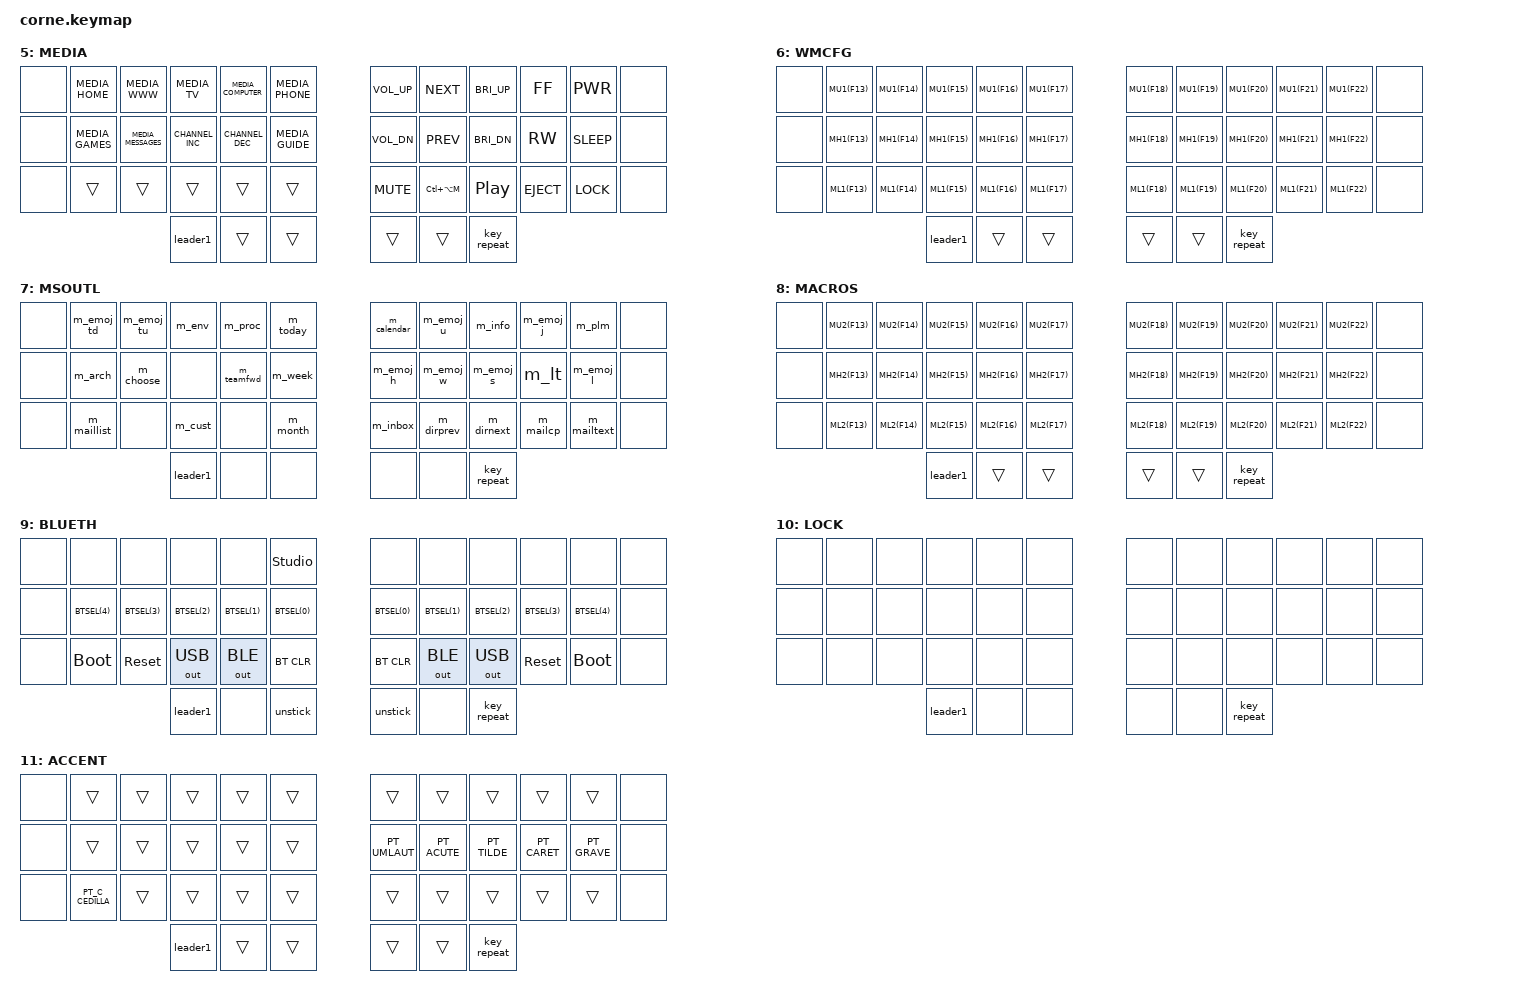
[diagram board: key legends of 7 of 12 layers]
/*
*
* Copyright (c) 2021 Darryl deHaan
* SPDX-License-Identifier: MIT
*
*/
#include <behaviors.dtsi>
#include <dt-bindings/zmk/keys.h>
#include <dt-bindings/zmk/bt.h>
#include <dt-bindings/zmk/outputs.h>
#include <dt-bindings/zmk/mouse.h>

#undef ZMK_POINTING_DEFAULT_MOVE_VAL
#define ZMK_POINTING_DEFAULT_MOVE_VAL 1500  // default: 600
#undef ZMK_POINTING_DEFAULT_SCRL_VAL
#define ZMK_POINTING_DEFAULT_SCRL_VAL 30    // default: 10
#include <dt-bindings/zmk/pointing.h>

#ifndef KEYMAP_DRAWER
#include <locale/keys_pt.h>
#endif

// https://github.com/urob/zmk-config/tree/main#timeless-homerow-mods
#define KEYS_L LT0 LT1 LT2 LT3 LT4 LM0 LM1 LM2 LM3 LM4 LB0 LB1 LB2 LB3 LB4  // left hand
#define KEYS_R RT0 RT1 RT2 RT3 RT4 RM0 RM1 RM2 RM3 RM4 RB0 RB1 RB2 RB3 RB4  // right hand
#define THUMBS LH2 LH1 LH0 RH0 RH1 RH2                                      // thumbs

#define QWERTY 0
#define NUMNAV 1
#define SYMBOL 2
#define FUNADJ 3
#define MOUSE  4
#define MEDIA  5
#define WMCFG  6
#define MSOUTL 7
#define MACROS 8
#define BLUETH 9
#define LOCK   10
#define ACCENT 11

#define COMBO_TIMEOUT 50
#define SPLIT_COMBO_TIMEOUT 75
// 3-finger chords land noticeably further apart than 2-finger ones; the extra
// slack stops S+D+F / X+C+V from missing the combo window. The idle guard -
// not the timeout - is what protects against false positives while typing.
#define LONG_COMBO_TIMEOUT 175
#define MACRO_TAP 10
#define MACRO_WAIT 0

// Upper row mods macro
#define URML(k1,k2,k3,k4,k5) &urm BLUETH k1  &urm MACROS k2  &urm MSOUTL k3  &urm WMCFG  k4  &urm MEDIA k5
#define URMR(k1,k2,k3,k4,k5) &urm MEDIA k1  &urm WMCFG  k2  &urm MSOUTL k3  &urm MACROS k4  &urm BLUETH k5
// Home row mods macro
#define HRML(k1,k2,k3,k4) &hm LGUI   k1  &hm LCTRL k2  &hm LALT  k3  &hms LSHIFT k4
#define HRMR(k1,k2,k3,k4) &hms RSHIFT k1  &hm LALT  k2  &hm LCTRL k3  &hm RGUI   k4
// Lower row mods macro
#define LRML(k1,k2,k3,k4) &kp k1  &hm RCTRL k2  &hm RALT  k3  &kp k4
#define LRMR(k1,k2,k3,k4) &kp k1  &hm RALT  k2  &hm RCTRL k3  &hm K_CMENU k4

// define AHK macro keys

// upper row for WMCFG layer (i.e. macro layer #1)
#define MU1(k) &kp LS(k)
// home row for WMCFG layer (i.e. macro layer #1)
#define MH1(k) &kp LA(k)
// lower row for WMCFG layer (i.e. macro layer #1)
#define ML1(k) &kp LC(k)

// upper row for WMCFG layer (i.e. macro layer #2)
#define MU2(k) &kp LG(LS(k))
// home row for WMCFG layer (i.e. macro layer #2)
#define MH2(k) &kp LG(LA(k))
// lower row for WMCFG layer (i.e. macro layer #2)
#define ML2(k) &kp LG(LC(k))

// more macros to shorten the definitions
#define BTSEL(profile) &bt BT_SEL profile
#define BTCLR &bt BT_CLR
#define OUTUSB &out OUT_USB
#define OUTBLE &out OUT_BLE

// TODO: add generic mechanism to lock layers
// TODO: add 2x rotary encoder - use Fxx or LANG1/LANG2 as free keycodes for AHK
// TODO: add leader key: move AHK into keyboard to use all all machines - use C_AL_CALC/C_AC_SEARCH/C_AL_CAL
// TODO: add trackball

// Sticky layer tuning: accent layer should not linger forever if you get
// distracted mid-composition. quick-release (the ZMK default for sticky
// layers) drops the layer as soon as the next key is pressed.
&sl {
    release-after-ms = <1500>;
};

/ {
// -------------------CORNE---------------------------------------
// |    |  1 |  2 |  3 |  4 |  5 | |  6 |  7 |  8 |  9 | 10 |    |
// |    | 13 | 14 | 15 | 16 | 17 | | 18 | 19 | 20 | 21 | 22 |    |
// |    | 25 | 26 | 27 | 28 | 29 | | 30 | 31 | 32 | 33 | 34 |    |
// |    |    |    | 36 | 37 | 38 | | 39 | 40 | 41 |    |    |    |

// -------------------TEMPEST-------------------------------------
//      |  0 |  1 |  2 |  3 |  4 | |  5 |  6 |  7 |  8 |  9 |
//      | 10 | 11 | 12 | 13 | 14 | | 15 | 16 | 17 | 18 | 19 |
//      | 20 | 21 | 22 | 23 | 24 | | 25 | 26 | 27 | 28 | 29 |
//                | 30 | 31 | 32 | | 33 | 34 | 35 |

// -------------------SWEEP---------------------------------------
//      |  0 |  1 |  2 |  3 |  4 | |  5 |  6 |  7 |  8 |  9 |
//      | 10 | 11 | 12 | 13 | 14 | | 15 | 16 | 17 | 18 | 19 |
//      | 20 | 21 | 22 | 23 | 24 | | 25 | 26 | 27 | 28 | 29 |
//                     | 30 | 31 | | 32 | 33 |
    combos {
        compatible = "zmk,combos";
        combo_toggle_lock_left {
                  timeout-ms = <COMBO_TIMEOUT>;
                  key-positions = <1 5 38>;  // ONLY-FOR-CORNE
                  require-prior-idle-ms = <150>;
                  layers = <QWERTY LOCK>;
                  bindings = <&tog LOCK>;
        };
        combo_toggle_lock_right {
                  timeout-ms = <COMBO_TIMEOUT>;
                  key-positions = <6 10 39>;  // ONLY-FOR-CORNE
                  require-prior-idle-ms = <150>;
                  layers = <QWERTY LOCK>;
                  bindings = <&tog LOCK>;
        };
        combo_esc {
                  timeout-ms = <COMBO_TIMEOUT>;
                  key-positions = <1 2>;  // ONLY-FOR-CORNE
                  require-prior-idle-ms = <120>;
                  layers = <QWERTY>;
                  bindings = <&kp ESC>;
        };
        combo_tab {
                  timeout-ms = <COMBO_TIMEOUT>;
                  key-positions = <13 14>;  // ONLY-FOR-CORNE
                  require-prior-idle-ms = <120>;
                  layers = <QWERTY>;
                  bindings = <&kp TAB>;
        };
        combo_ret {
                  timeout-ms = <COMBO_TIMEOUT>;
                  key-positions = <6 7>;  // ONLY-FOR-CORNE
                  require-prior-idle-ms = <120>;
                  layers = <QWERTY>;
                  bindings = <&kp RET>;
        };
        combo_capsword {
                  timeout-ms = <SPLIT_COMBO_TIMEOUT>;
                  key-positions = <17 18>;  // ONLY-FOR-CORNE
                  require-prior-idle-ms = <200>;
                  layers = <QWERTY>;
                  bindings = <&capsw>;
        };
        combo_bspc {
                  timeout-ms = <COMBO_TIMEOUT>;
                  key-positions = <21 22>;  // ONLY-FOR-CORNE
                  require-prior-idle-ms = <150>;
                  layers = <QWERTY>;
                  bindings = <&kp BSPC>;
        };
        combo_ctrlbspc {
                  timeout-ms = <COMBO_TIMEOUT>;
                  key-positions = <19 20>;  // ONLY-FOR-CORNE
                  require-prior-idle-ms = <150>;
                  layers = <QWERTY>;
                  bindings = <&kp LC(BSPC)>;
        };
        combo_del {
                  timeout-ms = <COMBO_TIMEOUT>;
                  key-positions = <9 10>;  // ONLY-FOR-CORNE
                  require-prior-idle-ms = <150>;
                  layers = <QWERTY>;
                  bindings = <&kp DEL>;
        };
        combo_repeat_right {
                  timeout-ms = <COMBO_TIMEOUT>;
                  key-positions = <18 19>;  // ONLY-FOR-CORNE
                  require-prior-idle-ms = <150>;
                  layers = <QWERTY>;
                  bindings = <&key_repeat>;
        };
        combo_sz {
                  timeout-ms = <COMBO_TIMEOUT>;
                  key-positions = <27 28>;  // ONLY-FOR-CORNE
                  require-prior-idle-ms = <100>;
                  layers = <QWERTY>;
                  bindings = <&kp RA(S)>;
        };
        combo_pup {
                  timeout-ms = <COMBO_TIMEOUT>;
                  key-positions = <4 5>;  // ONLY-FOR-CORNE
                  require-prior-idle-ms = <150>;
                  layers = <QWERTY>;
                  bindings = <&kp PG_UP>;
        };
        combo_down {
                  timeout-ms = <COMBO_TIMEOUT>;
                  key-positions = <16 17>;  // ONLY-FOR-CORNE
                  require-prior-idle-ms = <150>;
                  layers = <QWERTY>;
                  bindings = <&kp PG_DN>;
        };
        combo_prtwin {
                  timeout-ms = <COMBO_TIMEOUT>;
                  key-positions = <25 26>;  // ONLY-FOR-CORNE
                  require-prior-idle-ms = <150>;
                  layers = <QWERTY>;
                  bindings = <&kp PSCRN>;
        };
        combo_ctrlshiftc {
                  timeout-ms = <LONG_COMBO_TIMEOUT>;
                  key-positions = <14 15 16>;  // ONLY-FOR-CORNE
                  require-prior-idle-ms = <200>;
                  layers = <QWERTY>;
                  bindings = <&kp LC(LS(C))>;
        };
        // Ctrl-Shift-X (cut). W+E+R on tempest. Previously this was a double-tap
        // of the copy combo via &td_ctrl_cx; tap-dances cannot be driven by
        // combos (the combo's press/release is not a clean single tap, which
        // leaked a bare "c" and left Ctrl/Shift latched).
        combo_ctrlshiftx {
                  timeout-ms = <LONG_COMBO_TIMEOUT>;
                  key-positions = <4 5 6>;   // ONLY-FOR-CORNE
                  require-prior-idle-ms = <200>;
                  layers = <QWERTY>;
                  bindings = <&kp LC(LS(X))>;
        };
        combo_ctrlshiftv {
                  timeout-ms = <LONG_COMBO_TIMEOUT>;
                  key-positions = <26 27 28>;  // ONLY-FOR-CORNE
                  require-prior-idle-ms = <200>;
                  layers = <QWERTY>;
                  bindings = <&kp LC(LS(V))>;
        };
        combo_ctrl_a {
                  timeout-ms = <COMBO_TIMEOUT>;
                  key-positions = <31 32>;  // ONLY-FOR-CORNE
                  require-prior-idle-ms = <150>;
                  layers = <QWERTY>;
                  bindings = <&kp LC(A)>;
        };
        combo_ctrl_z {
                  timeout-ms = <COMBO_TIMEOUT>;
                  key-positions = <32 33>;  // ONLY-FOR-CORNE
                  require-prior-idle-ms = <150>;
                  layers = <QWERTY>;
                  bindings = <&kp LC(Z)>;
        };
        // Leader key 2 via the N+M combo (tempest positions 25/26).
        // NOTE: this partially overlaps combo_ctrl_a <26 27>. ZMK supports
        // overlapping combos, but N+M vs M+ may resolve ambiguously.
        combo_leader2 {
                  timeout-ms = <COMBO_TIMEOUT>;
                  key-positions = <20 21>;  // ONLY-FOR-CORNE
                  require-prior-idle-ms = <150>;
                  layers = <QWERTY>;
                  bindings = <&leader2>;
        };
    };

    macros {
        ZMK_MACRO(m_today,
                wait-ms = <MACRO_WAIT>;
                tap-ms = <MACRO_TAP>;
                bindings
                    = <&macro_press &kp LCTRL>
                    , <&macro_tap &kp F2>
                    , <&macro_release &kp LCTRL>
                    , <&macro_wait_time 300>
                    , <&macro_press &kp LCTRL &kp LSHIFT>
                    , <&macro_tap &kp N8>
                    , <&macro_release &kp LCTRL &kp LSHIFT>
                    ;
                )
        ZMK_MACRO(m_week,
                wait-ms = <MACRO_WAIT>;
                tap-ms = <MACRO_TAP>;
                bindings
                    = <&macro_press &kp LCTRL>
                    , <&macro_tap &kp F3>
                    , <&macro_release &kp LCTRL>
                    , <&macro_wait_time 300>
                    , <&macro_press &kp LCTRL &kp LSHIFT>
                    , <&macro_tap &kp N8>
                    , <&macro_release &kp LCTRL &kp LSHIFT>
                    ;
                )
        ZMK_MACRO(m_month,
                wait-ms = <MACRO_WAIT>;
                tap-ms = <MACRO_TAP>;
                bindings
                    = <&macro_press &kp LCTRL>
                    , <&macro_tap &kp F4>
                    , <&macro_release &kp LCTRL>
                    , <&macro_wait_time 300>
                    , <&macro_press &kp LCTRL &kp LSHIFT>
                    , <&macro_tap &kp N8>
                    , <&macro_release &kp LCTRL &kp LSHIFT>
                    ;
                )
        ZMK_MACRO(m_proc,
                wait-ms = <MACRO_WAIT>;
                tap-ms = <MACRO_TAP>;
                bindings
                    = <&macro_press &kp LCTRL &kp LSHIFT>
                    , <&macro_tap &kp N7>
                    , <&macro_release &kp LCTRL &kp LSHIFT>
                    ;
                )
        ZMK_MACRO(m_arch,
                wait-ms = <MACRO_WAIT>;
                tap-ms = <MACRO_TAP>;
                bindings
                    = <&macro_press &kp LCTRL &kp LSHIFT>
                    , <&macro_tap &kp N6>
                    , <&macro_release &kp LCTRL &kp LSHIFT>
                    ;
                )
        ZMK_MACRO(m_plm,
                wait-ms = <MACRO_WAIT>;
                tap-ms = <MACRO_TAP>;
                bindings
                    = <&macro_press &kp LCTRL &kp LSHIFT>
                    , <&macro_tap &kp N4>
                    , <&macro_release &kp LCTRL &kp LSHIFT>
                    ;
                )
        ZMK_MACRO(m_lt,
                wait-ms = <MACRO_WAIT>;
                tap-ms = <MACRO_TAP>;
                bindings
                    = <&macro_press &kp LCTRL &kp LSHIFT>
                    , <&macro_tap &kp N5>
                    , <&macro_release &kp LCTRL &kp LSHIFT>
                    ;
                )
        ZMK_MACRO(m_cust,
                wait-ms = <MACRO_WAIT>;
                tap-ms = <MACRO_TAP>;
                bindings
                    = <&macro_press &kp LCTRL &kp LSHIFT>
                    , <&macro_tap &kp N2>
                    , <&macro_release &kp LCTRL &kp LSHIFT>
                    ;
                )
        ZMK_MACRO(m_info,
                wait-ms = <MACRO_WAIT>;
                tap-ms = <MACRO_TAP>;
                bindings
                    = <&macro_press &kp LCTRL &kp LSHIFT>
                    , <&macro_tap &kp N3>
                    , <&macro_release &kp LCTRL &kp LSHIFT>
                    ;
                )
        ZMK_MACRO(m_env,
                wait-ms = <MACRO_WAIT>;
                tap-ms = <MACRO_TAP>;
                bindings
                    = <&macro_press &kp LCTRL &kp LSHIFT>
                    , <&macro_tap &kp N1>
                    , <&macro_release &kp LCTRL &kp LSHIFT>
                    ;
                )
        ZMK_MACRO(m_choose,
                wait-ms = <MACRO_WAIT>;
                tap-ms = <MACRO_TAP>;
                bindings
                    = <&macro_press &kp LCTRL &kp LSHIFT>
                    , <&macro_tap &kp N9>
                    , <&macro_release &kp LCTRL &kp LSHIFT>
                    ;
                )
        ZMK_MACRO(m_maillist,
                wait-ms = <MACRO_WAIT>;
                tap-ms = <MACRO_TAP>;
                bindings = <&kp LS(F6)>;
                )
        ZMK_MACRO(m_mailtext,
                wait-ms = <MACRO_WAIT>;
                tap-ms = <MACRO_TAP>;
                bindings = <&kp F6>;
                )
        ZMK_MACRO(m_teamfwd,
                wait-ms = <MACRO_WAIT>;
                tap-ms = <MACRO_TAP>;
                bindings = <&kp LS(F24)>;
                )
        ZMK_MACRO(m_calendar,
                wait-ms = <MACRO_WAIT>;
                tap-ms = <MACRO_TAP>;
                bindings = <&kp LC(N2)>;
                )
        ZMK_MACRO(m_inbox,
                wait-ms = <MACRO_WAIT>;
                tap-ms = <MACRO_TAP>;
                bindings = <&kp LC(LS(I))>;
                )
        ZMK_MACRO(m_dirprev,
                wait-ms = <MACRO_WAIT>;
                tap-ms = <MACRO_TAP>;
                bindings = <&kp LA(LEFT)>;
                )
        ZMK_MACRO(m_dirnext,
                wait-ms = <MACRO_WAIT>;
                tap-ms = <MACRO_TAP>;
                bindings = <&kp LC(RIGHT)>;
                )
        ZMK_MACRO(m_mailcp,
                wait-ms = <MACRO_WAIT>;
                tap-ms = <MACRO_TAP>;
                bindings = <&kp LC(LS(Y))>;
                )
        ZMK_MACRO(m_emoj_td,
                wait-ms = <MACRO_WAIT>;
                tap-ms = <MACRO_TAP>;
                bindings = <&kp RA(N9) &kp E &kp T &kp D &kp SPACE &kp BSPC>;
                )
        ZMK_MACRO(m_emoj_tu,
                wait-ms = <MACRO_WAIT>;
                tap-ms = <MACRO_TAP>;
                bindings = <&kp RA(N9) &kp E &kp T &kp U &kp SPACE &kp BSPC>;
                )
        ZMK_MACRO(m_emoj_u,
                wait-ms = <MACRO_WAIT>;
                tap-ms = <MACRO_TAP>;
                bindings = <&kp RA(N9) &kp E &kp T &kp SPACE &kp BSPC>;
                )
        ZMK_MACRO(m_emoj_j,
                wait-ms = <MACRO_WAIT>;
                tap-ms = <MACRO_TAP>;
                bindings = <&kp RA(N9) &kp E &kp J &kp SPACE &kp BSPC>;
                )
        ZMK_MACRO(m_emoj_l,
                wait-ms = <MACRO_WAIT>;
                tap-ms = <MACRO_TAP>;
                bindings = <&kp RA(N9) &kp E &kp L &kp SPACE &kp BSPC>;
                )
        ZMK_MACRO(m_emoj_h,
                wait-ms = <MACRO_WAIT>;
                tap-ms = <MACRO_TAP>;
                bindings = <&kp RA(N9) &kp E &kp H &kp SPACE &kp BSPC>;
                )
        ZMK_MACRO(m_emoj_s,
                wait-ms = <MACRO_WAIT>;
                tap-ms = <MACRO_TAP>;
                bindings = <&kp RA(N9) &kp E &kp S &kp SPACE &kp BSPC>;
                )
        ZMK_MACRO(m_emoj_w,
                wait-ms = <MACRO_WAIT>;
                tap-ms = <MACRO_TAP>;
                bindings = <&kp RA(N9) &kp E &kp W &kp SPACE &kp BSPC>;
                )
        ZMK_MACRO(m_dblclk,
                wait-ms = <MACRO_WAIT>;
                tap-ms = <MACRO_TAP>;
                bindings = <&mkp LCLK &mkp LCLK>;
                )
        // Cumps, / Heiko
        ZMK_MACRO(m_sig_cumps,
                wait-ms = <MACRO_WAIT>;
                tap-ms = <MACRO_TAP>;
        bindings = <&kp LS(C) &kp U &kp M &kp P &kp S &kp COMMA &kp RET &kp LS(H)
                    &kp E &kp I &kp K &kp O>;
                )

        // Muito obrigado, / Heiko
        ZMK_MACRO(m_sig_mo,
                wait-ms = <MACRO_WAIT>;
                tap-ms = <MACRO_TAP>;
        bindings = <&kp LS(M) &kp U &kp I &kp T &kp O &kp SPACE &kp O &kp B
                    &kp R &kp I &kp G &kp A &kp D &kp O &kp COMMA &kp RET
                    &kp LS(H) &kp E &kp I &kp K &kp O>;
                )

        // Obrigado, / Heiko
        ZMK_MACRO(m_sig_o,
                wait-ms = <MACRO_WAIT>;
                tap-ms = <MACRO_TAP>;
        bindings = <&kp LS(O) &kp B &kp R &kp I &kp G &kp A &kp D &kp O
                    &kp COMMA &kp RET &kp LS(H) &kp E &kp I &kp K &kp O>;
                )

        // Obrigado e cumps, / Heiko
        ZMK_MACRO(m_sig_oc,
                wait-ms = <MACRO_WAIT>;
                tap-ms = <MACRO_TAP>;
        bindings = <&kp LS(O) &kp B &kp R &kp I &kp G &kp A &kp D &kp O
                    &kp SPACE &kp E &kp SPACE &kp C &kp U &kp M &kp P &kp S
                    &kp COMMA &kp RET &kp LS(H) &kp E &kp I &kp K &kp O>;
                )

        // Cumps e obrigado, / Heiko
        ZMK_MACRO(m_sig_co,
                wait-ms = <MACRO_WAIT>;
                tap-ms = <MACRO_TAP>;
        bindings = <&kp LS(C) &kp U &kp M &kp P &kp S &kp SPACE &kp E &kp SPACE
                    &kp O &kp B &kp R &kp I &kp G &kp A &kp D &kp O
                    &kp COMMA &kp RET &kp LS(H) &kp E &kp I &kp K &kp O>;
                )

        // Best regards, / Heiko
        ZMK_MACRO(m_sig_br,
                wait-ms = <MACRO_WAIT>;
                tap-ms = <MACRO_TAP>;
        bindings = <&kp LS(B) &kp E &kp S &kp T &kp SPACE &kp R &kp E &kp G
                    &kp A &kp R &kp D &kp S &kp COMMA &kp RET &kp LS(H) &kp E
                    &kp I &kp K &kp O>;
                )

        // Thank you, / Heiko
        ZMK_MACRO(m_sig_ty,
                wait-ms = <MACRO_WAIT>;
                tap-ms = <MACRO_TAP>;
        bindings = <&kp LS(T) &kp H &kp A &kp N &kp K &kp SPACE &kp Y &kp O
                    &kp U &kp COMMA &kp RET &kp LS(H) &kp E &kp I &kp K &kp O>;
                )

        // Thank you and best regards, / Heiko
        ZMK_MACRO(m_sig_tb,
                wait-ms = <MACRO_WAIT>;
                tap-ms = <MACRO_TAP>;
        bindings = <&kp LS(T) &kp H &kp A &kp N &kp K &kp SPACE &kp Y &kp O
                    &kp U &kp SPACE &kp A &kp N &kp D &kp SPACE &kp B &kp E
                    &kp S &kp T &kp SPACE &kp R &kp E &kp G &kp A &kp R
                    &kp D &kp S &kp COMMA &kp RET &kp LS(H) &kp E &kp I &kp K
                    &kp O>;
                )

        // Thank you, / Heiko Riemer
        ZMK_MACRO(m_sig_th,
                wait-ms = <MACRO_WAIT>;
                tap-ms = <MACRO_TAP>;
        bindings = <&kp LS(T) &kp H &kp A &kp N &kp K &kp SPACE &kp Y &kp O
                    &kp U &kp COMMA &kp RET &kp LS(H) &kp E &kp I &kp K &kp O
                    &kp SPACE &kp LS(R) &kp I &kp E &kp M &kp E &kp R>;
                )

        // You're Welcome
        ZMK_MACRO(m_sig_yw,
                wait-ms = <MACRO_WAIT>;
                tap-ms = <MACRO_TAP>;
        bindings = <&kp LS(Y) &kp O &kp U &kp SQT &kp R &kp E &kp SPACE &kp LS(W)
                    &kp E &kp L &kp C &kp O &kp M &kp E>;
                )

        // Ctrl-B "Agenda:" Ctrl-B, then bullet
        ZMK_MACRO(m_ag,
                wait-ms = <MACRO_WAIT>;
                tap-ms = <MACRO_TAP>;
                bindings = <&kp LC(B) &kp A &kp G &kp E &kp N &kp D &kp A &kp PT_COLON &kp LC(B) &kp RET &kp LC(LS(L))>;
                )

        // Ctrl-B "Objective:" Ctrl-B, then bullet
        ZMK_MACRO(m_ob,
                wait-ms = <MACRO_WAIT>;
                tap-ms = <MACRO_TAP>;
                bindings = <&kp LC(B) &kp O &kp B &kp J &kp E &kp C &kp T &kp I &kp V &kp E &kp PT_COLON &kp LC(B) &kp RET &kp LC(LS(L))>;
                )

        // Ctrl-B "Actions:" Ctrl-B, then bullet
        ZMK_MACRO(m_ac,
                wait-ms = <MACRO_WAIT>;
                tap-ms = <MACRO_TAP>;
                bindings = <&kp LC(B) &kp A &kp C &kp T &kp I &kp O &kp N &kp S &kp PT_COLON &kp LC(B) &kp RET &kp LC(LS(L))>;
                )

        // Agenda: block then Objective: block
        ZMK_MACRO(m_ao,
                wait-ms = <MACRO_WAIT>;
                tap-ms = <MACRO_TAP>;
                bindings = <&kp LC(B) &kp A &kp G &kp E &kp N &kp D &kp A &kp PT_COLON &kp LC(B) &kp RET &kp LC(LS(L)) &kp SPACE &kp RET &kp RET &kp RET &kp LC(B) &kp O &kp B &kp J &kp E &kp C &kp T &kp I &kp V &kp E &kp PT_COLON &kp LC(B) &kp RET &kp LC(LS(L))>;
                )
        ZMK_MACRO(m_de_ue,
                wait-ms = <MACRO_WAIT>;
                tap-ms = <MACRO_TAP>;
                bindings = <&kp PT_UMLAUT &kp U>;
                )
    };

    behaviors {
        spc_ret: space_return {
            compatible = "zmk,behavior-mod-morph";
            #binding-cells = <0>;
            bindings = <&kp PT_SPACE>, <&kp RET>;
            mods = <(MOD_LALT)>;
        };
        bspc_del: backspace_delete {
            compatible = "zmk,behavior-mod-morph";
            #binding-cells = <0>;
            bindings = <&kp BACKSPACE>, <&kp DELETE>;
            mods = <(MOD_LSFT|MOD_RSFT)>;
            /*keep-mods = <(MOD_RSFT)>;*/
        };
        laquo_raquo: laquo_raquo {
            compatible = "zmk,behavior-mod-morph";
            #binding-cells = <0>;
            bindings = <&kp PT_LAQUO>, <&kp PT_RAQUO>;
            mods = <(MOD_LSFT|MOD_RSFT)>;
        };
        ordm_ordf: ordm_ordf {
            compatible = "zmk,behavior-mod-morph";
            #binding-cells = <0>;
            bindings = <&kp PT_ORDM>, <&kp PT_ORDF>;
            mods = <(MOD_LSFT|MOD_RSFT)>;
        };
        hm: homerow_mods {
            compatible = "zmk,behavior-hold-tap";
            #binding-cells = <2>;
            tapping-term-ms = <210>;
            require-prior-idle-ms = <150>;
            flavor = "tap-preferred";
            bindings = <&kp>, <&kp>;
        };
        hms: homerow_mod_shift {
            compatible = "zmk,behavior-hold-tap";
            #binding-cells = <2>;
            tapping-term-ms = <200>;
            require-prior-idle-ms = <125>;
            flavor = "balanced";
            bindings = <&kp>, <&kp>;
        };
        urm: upper_row_mods {
            compatible = "zmk,behavior-hold-tap";
            #binding-cells = <2>;
            tapping-term-ms = <250>;
            require-prior-idle-ms = <150>;
            flavor = "tap-preferred";
            bindings = <&mo>, <&kp>;
        };
        trm: thumb_row_mods {
            compatible = "zmk,behavior-hold-tap";
            #binding-cells = <2>;
            tapping-term-ms = <250>;
            require-prior-idle-ms = <50>;
            flavor = "tap-preferred";
            bindings = <&mo>, <&kp>;
         };
         skm: space_key_mod {  //TODO(heiko): not yet used
            compatible = "zmk,behavior-hold-tap";
            #binding-cells = <2>;
            tapping-term-ms = <250>;
            require-prior-idle-ms = <150>;
            flavor = "tap-preferred";
            /*bindings = <&mo>, <&spc_ret>;*/
            bindings = <&mo>, <&kp>;
        };
        unstick: unstick {
            compatible = "zmk,behavior-macro";
            #binding-cells = <0>;
            bindings = <&kp LSHIFT &kp RSHIFT &kp LCTRL &kp RCTRL &kp LALT &kp RALT &kp LGUI &kp RGUI>;
        };
        capsw: behavior_caps_word {
            compatible = "zmk,behavior-caps-word";
            #binding-cells = <0>;
            continue-list = <BACKSPACE DELETE PT_MINUS PT_UNDER>;
        };
        // Leader key instances. Reach the first instance with the left outer
        // thumb and the second with the N+M combo. Note: generate_keymaps.sh
        // rewrites the &leader1 placeholder token to this behavior, so the behavior
        // must stay defined here in the shared source.
        //
        // leader1 = the AHK replacement sequences (previously typed as "]xx").
        //           The leader key itself replaces the "]" prefix, so "]c"
        //           becomes leader1 then C.
        leader1: leader1 {
            compatible = "zmk,behavior-leader-key";
            #binding-cells = <0>;
            // Portuguese / English sign-offs
            cu  { sequence = <C U>;   bindings = <&m_sig_cumps>; };
            obr { sequence = <O B R>; bindings = <&m_sig_o>; };
            mo  { sequence = <M O>;   bindings = <&m_sig_mo>; };
            oc  { sequence = <O C>;   bindings = <&m_sig_oc>; };
            co  { sequence = <C O>;   bindings = <&m_sig_co>; };
            br  { sequence = <B R>;   bindings = <&m_sig_br>; };
            ty  { sequence = <T Y>;   bindings = <&m_sig_ty>; };
            tb  { sequence = <T B>;   bindings = <&m_sig_tb>; };
            th  { sequence = <T H>;   bindings = <&m_sig_th>; };
            yw  { sequence = <Y W>;   bindings = <&m_sig_yw>; };
            // MS Outlook headings (AHK "^b" = Ctrl-B)
            ag  { sequence = <A G>;   bindings = <&m_ag>; };
            obj { sequence = <O B J>; bindings = <&m_ob>; };
            ao  { sequence = <A O>;   bindings = <&m_ao>; };
            ac  { sequence = <A C>;   bindings = <&m_ac>; };
        };

        // leader2 = system / bluetooth sequences.
        leader2: leader2 {
            compatible = "zmk,behavior-leader-key";
            #binding-cells = <0>;
            usb { sequence = <U S B>; bindings = <&out OUT_USB>; };
            ble { sequence = <B L E>; bindings = <&out OUT_BLE>; };
            bt0 { sequence = <B N0>; bindings = <&bt BT_SEL 0>; };
            bt1 { sequence = <B N1>; bindings = <&bt BT_SEL 1>; };
            bt2 { sequence = <B N2>; bindings = <&bt BT_SEL 2>; };
            btc { sequence = <C L E A R>; bindings = <&bt BT_CLR>; };
            boot { sequence = <B O O T>; bindings = <&bootloader>; };
            reset { sequence = <R E S E T>; bindings = <&sys_reset>; };
        };

    };

        keymap {
                compatible = "zmk,keymap";

                default_layer {
                        display-name = "QWERTY";
// -------------------------------------------------------------------------------
// |      |Q/L9 |W/L8 |E/L7 |R/L6 |T/L5 |   |Y/L5 |U/L6 |I/L7 |O/L8 |P/L9 |      |
// |      |A/LG |S/LC |D/LA |F/LS |  G  |   |  H  |J/RS |K/LA |L/LC |;/RG |      |
// |      |Z/LS |X/RC |C/RA |  V  |  B  |   |  N  | M   |,/RA |./RC |//MENU|     |
//              |     | L1  |S/LC |              |SPC/L4| L2  |     |
                        bindings = <
&none URML(Q, W, E, R, T)        URMR(Y, U, I, O, P) &none
&none HRML(A, S, D, F) &kp G     &kp H HRMR(J, K, L, PT_C_CEDILLA) &none
&none LRML(Z, X, C, V) &kp B     &kp N LRMR(M, COMMA, DOT, PT_MINUS) &none
  &leader1 &mo NUMNAV  &kp BACKSPACE     &skm MOUSE SPACE &mo SYMBOL &key_repeat
                        >;
                };

                numnav_layer {
                        display-name = "NUMNAV";
// -------------------------------------------------------------------------------
// |      |  1  |  2  |  3  |  4  |  5  |   |  6  |  7  |  8  |  9  |  0  |      |
// |      |     |     |     |     |     |   |LF/RS|DN/LA|UP/LC|RT/LG|     |      |
// |      |     |     |     |     |     |   |  «  |  º  |     |     |     |      |
//                    |     |     |     |   |     | L3  |     |
                        bindings = <
 &none &kp N1 &kp N2 &kp N3  &kp N4 &kp N5     &kp N6  &kp N7  &kp N8  &kp N9  &kp N0  &none
 &none &trans &trans &trans &trans &trans      &kp LEFT HRMR(DOWN, UP, RIGHT, RIGHT) &none
 &none &trans &trans &trans &trans &trans      &laquo_raquo &ordm_ordf &trans &trans &trans &none
                     &leader1  &trans  &trans    &trans &mo FUNADJ &key_repeat
                        >;
                };

                symbol_layer {
                        display-name = "SYMBOL";
// -------------------------------------------------------------------------------
// |      |  !  |  "@ |  #  |  $  |  %  |   |  &^ |  /& |  (* |  )( |  =) |      |
// |      |  <  |  [  |  {  |  (  | ACC |   |  '- |  \= |  *{ |  `} |  ^| |      |
// |      |  >  |  ]  |  }  |  )  |  ~  |   |  ?_ |  |+ |  +[ |  '] |  ~\ |      |
//                    |     | L3  | DEL |   |     |     |     |
                        bindings = <
&none &kp PT_EXCL &kp PT_DQT &kp PT_HASH &kp PT_DLLR &kp PT_PRCNT  &kp PT_AMPS &kp PT_FSLH &kp PT_LPAR &kp PT_RPAR &kp PT_EQUAL &none
&none HRML(PT_LT, PT_LBKT, PT_LBRC, PT_LPAR) &sl ACCENT  &kp PT_SQT HRMR(PT_BSLH, PT_STAR, PT_AT, PT_UNDER) &none
&none LRML(PT_GT, PT_RBKT, PT_RBRC, PT_RPAR) &kp PT_TILDE  &kp PT_QMARK LRMR(PT_PIPE, PT_PLUS, PT_EURO, PT_SECT) &none
                        &leader1 &mo FUNADJ &hm RCTRL DEL   &trans  &trans   &key_repeat
                        >;
                };

                funadj_layer {
                        display-name = "FUNADJ";
// -------------------------------------------------------------------------------
// |      | F1  | F2  | F3  | F4  | F5  |   | F6  | F7  | F8  | F9  | F10 |      |
// |      | F11 | F12 | F13 | F14 | F15 |   | F16 | F17 | F18 | F19 | F20 |      |
// |      |PSCRN|SLCK |BREAK|     | CAPS|   | HOME| PDN | PUP | END | INS |      |
//                    |     |     |     |   |     |     |     |
                        bindings = <
&none &kp F1 &kp F2 &kp F3 &kp F4 &kp F5       &kp F6 &kp F7 &kp F8 &kp F9 &kp F10 &none
&none HRML(F11, F12, F13, F14) &kp F15         &kp F16 HRMR(F17, F18, F19, F20) &none
&none LRML(PSCRN, SLCK, PAUSE_BREAK, CAPS) &trans  &kp HOME LRMR(PG_DN, PG_UP, END, INS) &none
                       &leader1 &trans &trans  &trans &trans &key_repeat
                        >;
                };

                mouse_layer {
                        display-name = "MOUSE";
// -------------------------------------------------------------------------------
// |      |     |     |  `  |  ´  |  ^  |   |     |     |     |     |     |      |
// |      | SUP | LC  | LA  | LS  |  ¨  |   | LF  | DN  | UP  | RT  | SUP |      |
// |      | SDN | RCLK| MCLK| LCLK|  ~  |   |     | LCLK| MCLK| RCLK| SDN |      |
//                    |     |     |     |   |     |     |     |
 // &none &trans &trans &kp LS(RBKT)  &kp RBKT &kp LS(BSLH)     &trans  &trans  &trans  &trans  &trans  &none
 // &none &msc SCRL_UP &kp LCTRL &kp LALT &kp LSHIFT &kp RA(LBKT)  &mmv MOVE_LEFT &mmv MOVE_DOWN &mmv MOVE_UP &mmv MOVE_RIGHT &msc SCRL_UP &none
 // &none &msc SCRL_DOWN &mkp RCLK &mkp MCLK &mkp LCLK &kp BSLH   &trans  &mkp LCLK &mkp MCLK &mkp RCLK &msc SCRL_DOWN &none
                        bindings = <
 &none &trans &trans &kp PT_GRAVE  &kp PT_ACUTE &kp PT_CARET  &msc SCRL_LEFT  &msc SCRL_DOWN  &msc SCRL_UP  &msc SCRL_RIGHT  &kp LC(LA(LS(J)))  &none
 &none &mkp MB5 &kp LCTRL &kp LALT &kp LSHIFT &kp PT_UMLAUT  &mmv MOVE_LEFT &mmv MOVE_DOWN &mmv MOVE_UP &mmv MOVE_RIGHT &mkp MB5 &none
 &none &mkp MB4 &mkp RCLK &mkp MCLK &mkp LCLK &kp PT_TILDE   &m_dblclk  &mkp LCLK &mkp MCLK &mkp RCLK &mkp MB4 &none
                     &leader1  &trans  &trans     &trans &trans &key_repeat
                        >;
                };

                config_layer {
                        display-name = "MEDIA";
// -------------------------------------------------------------------------------
// |      |     |     |     |     |     |   | VUP | NXT | BUP |     |     |      |
// |      |     |     |     |     |     |   | VDN | PRE | BDN |     |     |      |
// |      | PWR | SLP | LCK |     |     |   | MT  |     | PP  |     | EJC |      |
//                    |     |     |     |   |     |     |     |
                        bindings = <
&none &kp C_MEDIA_HOME &kp C_MEDIA_WWW &kp C_MEDIA_TV &kp C_MEDIA_COMPUTER &kp C_MEDIA_PHONE  &kp C_VOL_UP &kp C_NEXT &kp C_BRI_UP &kp C_FF &kp C_PWR &none
&none &kp C_MEDIA_GAMES &kp C_MEDIA_MESSAGES &kp C_CHANNEL_INC &kp C_CHANNEL_DEC &kp C_MEDIA_GUIDE  &kp C_VOL_DN &kp C_PREV &kp C_BRI_DN &kp C_RW &kp C_SLEEP &none
&none &trans &trans &trans &trans &trans  &kp C_MUTE &kp LC(LA(M)) &kp C_PP &kp C_EJECT &kp K_LOCK &none
                &leader1 &trans &trans   &trans &trans &key_repeat
                        >;
                };

                wmcfg_layer {
                        display-name = "WMCFG";
// -------------------------------------------------------------------------------
// |      |S-F13|S-F14|S-F15|S-F16|S-F17|   |S-F18|S-F19|S-F20|S-F21|S-F22|      |
// |      |A-F13|A-F14|A-F15|A-F16|A-F17|   |A-F18|A-F19|A-F20|A-F21|A-F22|      |
// |      |C-F13|C-F14|C-F15|C-F16|C-F17|   |C-F18|C-F19|C-F20|C-F21|C-F22|      |
//                    |     |     |     |   |     |     |     |
                        bindings = <
&none MU1(F13) MU1(F14) MU1(F15) MU1(F16) MU1(F17) MU1(F18) MU1(F19) MU1(F20) MU1(F21) MU1(F22)  &none
&none MH1(F13) MH1(F14) MH1(F15) MH1(F16) MH1(F17) MH1(F18) MH1(F19) MH1(F20) MH1(F21) MH1(F22)  &none
&none ML1(F13) ML1(F14) ML1(F15) ML1(F16) ML1(F17) ML1(F18) ML1(F19) ML1(F20) ML1(F21) ML1(F22)  &none
                      &leader1 &trans &trans        &trans &trans &key_repeat
                        >;
                };

                outl_layer {
                        display-name = "MSOUTL";
// -------------------------------------------------------------------------------
// |   👎 |   👍|     | ENV | PROC|  TD |   | CAL | 🤔  | INFO| 😜  | PLM |      |
// |      | ARCH| SEL |     |S-F24|  W  |   | 😊  | 😉  | 😢  | LT  | 🤣  |      |
// |      | <-- |     | CUST|     |  M  |   | INB | NXT | PRV | FSEL| --> |      |
//                    |     |     |     |   |     |     |     |
                        bindings = <
&none &m_emoj_td &m_emoj_tu &m_env &m_proc &m_today  &m_calendar &m_emoj_u &m_info &m_emoj_j &m_plm &none
&none &m_arch &m_choose &none &m_teamfwd &m_week  &m_emoj_h &m_emoj_w &m_emoj_s &m_lt &m_emoj_l &none
&none &m_maillist &none &m_cust &none &m_month  &m_inbox &m_dirprev &m_dirnext &m_mailcp &m_mailtext &none
                     &leader1 &none &none  &none &none &key_repeat
                        >;
                };

                macros_layer {
                        display-name = "MACROS";
// -------------------------------------------------------------------------------
// |      |S-F13|S-F14|S-F15|S-F16|S-F17|   |S-F18|S-F19|S-F20|S-F21|S-F22|      |
// |      |A-F13|A-F14|A-F15|A-F16|A-F17|   |A-F18|A-F19|A-F20|A-F21|A-F22|      |
// |      |C-F13|C-F14|C-F15|C-F16|C-F17|   |C-F18|C-F19|C-F20|C-F21|C-F22|      |
//                    |     |     |     |   |     |     |     |
                        bindings = <
&none MU2(F13) MU2(F14) MU2(F15) MU2(F16) MU2(F17) MU2(F18) MU2(F19) MU2(F20) MU2(F21) MU2(F22)  &none
&none MH2(F13) MH2(F14) MH2(F15) MH2(F16) MH2(F17) MH2(F18) MH2(F19) MH2(F20) MH2(F21) MH2(F22)  &none
&none ML2(F13) ML2(F14) ML2(F15) ML2(F16) ML2(F17) ML2(F18) ML2(F19) ML2(F20) ML2(F21) ML2(F22)  &none
                      &leader1 &trans &trans        &trans &trans &key_repeat
                        >;
                };

                bt_layer {
                        display-name = "BLUETH";
// -------------------------------------------------------------------------------
// |      |     |     |     |     |     |   |     |     |     |     |     |      |
// |      | #4  | #3  | #2  | #1  | #0  |   | #0  | #1  | #2  | #3  | #4  |      |
// |      | BL  | RST | USB | BLE | CLR |   | CLR | BLE | USB | RST | BL  |      |
//                    |     |     |     |   |     |     |     |
                        bindings = <
&none &none  &none  &none  &none  &studio_unlock   &none  &none  &none  &none  &none  &none
&none BTSEL(4) BTSEL(3) BTSEL(2) BTSEL(1) BTSEL(0) BTSEL(0) BTSEL(1) BTSEL(2) BTSEL(3) BTSEL(4) &none
&none &bootloader &sys_reset OUTUSB OUTBLE BTCLR    BTCLR  OUTBLE  OUTUSB  &sys_reset  &bootloader  &none
                      &leader1 &none &unstick        &unstick &none &key_repeat
                        >;
                };

                lock_layer {
                        display-name = "LOCK";
                        bindings = <
&none &none &none &none &none &none  &none &none &none &none &none &none
&none &none &none &none &none &none  &none &none &none &none &none &none
&none &none &none &none &none &none  &none &none &none &none &none &none
                  &leader1 &none &none  &none &none &key_repeat
                        >;
                };
                // One-shot accent layer: dead keys live on the RIGHT hand so the
                // LEFT hand is free to press the vowel being accented.
                // Reach it with &sl ACCENT (sticky layer) - no hold, no timing.
                // Home row is ordered by frequency: umlaut (de) first, then the
                // Portuguese marks acute, tilde, circumflex, grave.
                accent_layer {
                        display-name = "ACCENT";
// -------------------------------------------------------------------------------
// |      |     |     |     |     |     |   |     |     |     |     |     |      |
// |      |     |     |     |     |     |   |  ¨  |  ´  |  ~  |  ^  |  `  |      |
// |      |  ç  |     |     |     |     |   |     |     |     |     |     |      |
//                    |     |     |     |   |     |     |     |
                        bindings = <
 &none &trans &trans &trans &trans &trans  &trans &trans &trans &trans &trans &none
 &none &trans &trans &trans &trans &trans  &kp PT_UMLAUT &kp PT_ACUTE &kp PT_TILDE &kp PT_CARET &kp PT_GRAVE &none
 &none &kp PT_C_CEDILLA &trans &trans &trans &trans  &trans &trans &trans &trans &trans &none
                     &leader1 &trans &trans  &trans &trans &key_repeat
                        >;
                };
                extra2 {
                       status = "reserved";
                };
        };
};

// vim: ft=c
